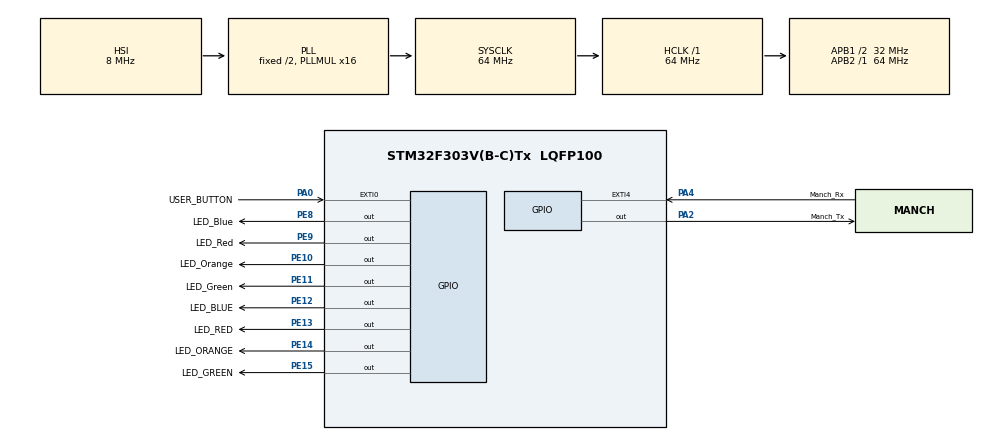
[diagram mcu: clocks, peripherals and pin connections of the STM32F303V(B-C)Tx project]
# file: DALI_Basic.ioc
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Mcu.Family=STM32F3
Mcu.Name=STM32F303V(B-C)Tx
Mcu.Package=LQFP100
NVIC.EXTI0_IRQn=true\:1\:0\:true\:false\:true\:true
NVIC.EXTI4_IRQn=true\:1\:0\:true\:false\:true\:true
NVIC.PriorityGroup=NVIC_PRIORITYGROUP_4
NVIC.TIM2_IRQn=true\:1\:0\:true\:false\:true\:true
PA0.GPIO_Label=USER_BUTTON
PA0.GPIO_PuPd=GPIO_PULLDOWN
PA0.Signal=GPXTI0
PA2.GPIO_Label=Manch_Tx
PA2.GPIO_PuPd=GPIO_PULLDOWN
PA2.Signal=GPIO_Output
PA4.GPIO_Label=Manch_Rx
PA4.GPIO_PuPd=GPIO_PULLDOWN
PA4.Signal=GPXTI4
PE10.GPIO_Label=LED_Orange
PE10.GPIO_PuPd=GPIO_PULLDOWN
PE10.Signal=GPIO_Output
PE11.GPIO_Label=LED_Green
PE11.GPIO_PuPd=GPIO_PULLDOWN
PE11.Signal=GPIO_Output
PE12.GPIO_Label=LED_BLUE
PE12.GPIO_PuPd=GPIO_PULLDOWN
PE12.Signal=GPIO_Output
PE13.GPIO_Label=LED_RED
PE13.GPIO_PuPd=GPIO_PULLDOWN
PE13.Signal=GPIO_Output
PE14.GPIO_Label=LED_ORANGE
PE14.GPIO_PuPd=GPIO_PULLDOWN
PE14.Signal=GPIO_Output
PE15.GPIO_Label=LED_GREEN
PE15.GPIO_PuPd=GPIO_PULLDOWN
PE15.Signal=GPIO_Output
PE8.GPIO_Label=LED_Blue
PE8.GPIO_PuPd=GPIO_PULLDOWN
PE8.Signal=GPIO_Output
PE9.GPIO_Label=LED_Red
PE9.GPIO_PuPd=GPIO_PULLDOWN
PE9.Signal=GPIO_Output
ProjectManager.HeapSize=0x200
ProjectManager.StackSize=0x400
ProjectManager.TargetToolchain=Makefile
RCC.AHBFreq_Value=64000000
RCC.APB1CLKDivider=RCC_HCLK_DIV2
RCC.APB1Freq_Value=32000000
RCC.APB1TimFreq_Value=64000000
RCC.APB2Freq_Value=64000000
RCC.APB2TimFreq_Value=64000000
RCC.CortexFreq_Value=64000000
RCC.HCLKFreq_Value=64000000
RCC.HSE_VALUE=8000000
RCC.HSI_VALUE=8000000
RCC.LSE_VALUE=32768
RCC.PLLMUL=RCC_PLL_MUL16
RCC.SYSCLKFreq_VALUE=64000000
RCC.SYSCLKSourceVirtual=RCC_SYSCLKSOURCE_PLLCLK
RCC.USBFreq_Value=64000000
TIM2.AutoReloadPreload=TIM_AUTORELOAD_PRELOAD_ENABLE
TIM2.Period=103
TIM2.Prescaler=63
VP_TIM2_VS_ClockSourceINT.Mode=Internal
board=DALI_Basic

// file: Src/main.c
/**
  ******************************************************************************
  * File Name          : main.c
  * Description        : Main program body
  ******************************************************************************
  ** This notice applies to any and all portions of this file
  * that are not between comment pairs USER CODE BEGIN and
  * USER CODE END. Other portions of this file, whether
  * inserted by the user or by software development tools
  * are owned by their respective copyright owners.
  *
  * COPYRIGHT(c) 2017 STMicroelectronics
  *
  * Redistribution and use in source and binary forms, with or without modification,
  * are permitted provided that the following conditions are met:
  *   1. Redistributions of source code must retain the above copyright notice,
  *      this list of conditions and the following disclaimer.
  *   2. Redistributions in binary form must reproduce the above copyright notice,
  *      this list of conditions and the following disclaimer in the documentation
  *      and/or other materials provided with the distribution.
  *   3. Neither the name of STMicroelectronics nor the names of its contributors
  *      may be used to endorse or promote products derived from this software
  *      without specific prior written permission.
  *
  * THIS SOFTWARE IS PROVIDED BY THE COPYRIGHT HOLDERS AND CONTRIBUTORS "AS IS"
  * AND ANY EXPRESS OR IMPLIED WARRANTIES, INCLUDING, BUT NOT LIMITED TO, THE
  * IMPLIED WARRANTIES OF MERCHANTABILITY AND FITNESS FOR A PARTICULAR PURPOSE ARE
  * DISCLAIMED. IN NO EVENT SHALL THE COPYRIGHT HOLDER OR CONTRIBUTORS BE LIABLE
  * FOR ANY DIRECT, INDIRECT, INCIDENTAL, SPECIAL, EXEMPLARY, OR CONSEQUENTIAL
  * DAMAGES (INCLUDING, BUT NOT LIMITED TO, PROCUREMENT OF SUBSTITUTE GOODS OR
  * SERVICES; LOSS OF USE, DATA, OR PROFITS; OR BUSINESS INTERRUPTION) HOWEVER
  * CAUSED AND ON ANY THEORY OF LIABILITY, WHETHER IN CONTRACT, STRICT LIABILITY,
  * OR TORT (INCLUDING NEGLIGENCE OR OTHERWISE) ARISING IN ANY WAY OUT OF THE USE
  * OF THIS SOFTWARE, EVEN IF ADVISED OF THE POSSIBILITY OF SUCH DAMAGE.
  *
  ******************************************************************************
  */

#include "main.h"
#include "stm32f3xx_hal.h"

/* USER CODE BEGIN Includes */
/* ++++++++++ Includes ++++++++++++++++++++++++++++++++++++++++++++++++++++++*/
// skipped timer_slave.h as I don't need it!
#include "DALI_Slave_ll.h"
#include "DALI_Slave_defs.h"
#include "DALI_defs.h"
/* USER CODE END Includes */

TIM_HandleTypeDef htim2;

/* USER CODE BEGIN PV */
/* Private variables ---------------------------------------------------------*/

/* USER CODE END PV */

void SystemClock_Config(void);
static void MX_GPIO_Init(void);
static void MX_TIM2_Init(void);

/* USER CODE BEGIN PFP */
/* Private function prototypes -----------------------------------------------*/

/* USER CODE END PFP */

int main(void)
{

  /* MCU Configuration----------------------------------------------------------*/

  /* Reset of all peripherals, Initializes the Flash interface and the Systick. */
  HAL_Init();

  /* Configure the system clock */
  SystemClock_Config();

  /* Initialize all configured peripherals */
  MX_GPIO_Init();
  MX_TIM2_Init();

  /* Infinite loop */
  while (1)
  {

  }

}

/** System Clock Configuration
*/
void SystemClock_Config(void)
{

  RCC_OscInitTypeDef RCC_OscInitStruct;
  RCC_ClkInitTypeDef RCC_ClkInitStruct;

    /**Initializes the CPU, AHB and APB busses clocks
    */
  RCC_OscInitStruct.OscillatorType = RCC_OSCILLATORTYPE_HSI;
  RCC_OscInitStruct.HSIState = RCC_HSI_ON;
  RCC_OscInitStruct.HSICalibrationValue = 16;
  RCC_OscInitStruct.PLL.PLLState = RCC_PLL_ON;
  RCC_OscInitStruct.PLL.PLLSource = RCC_PLLSOURCE_HSI;
  RCC_OscInitStruct.PLL.PLLMUL = RCC_PLL_MUL16;
  if (HAL_RCC_OscConfig(&RCC_OscInitStruct) != HAL_OK)
  {
    _Error_Handler(__FILE__, __LINE__);
  }

    /**Initializes the CPU, AHB and APB busses clocks
    */
  RCC_ClkInitStruct.ClockType = RCC_CLOCKTYPE_HCLK|RCC_CLOCKTYPE_SYSCLK
                              |RCC_CLOCKTYPE_PCLK1|RCC_CLOCKTYPE_PCLK2;
  RCC_ClkInitStruct.SYSCLKSource = RCC_SYSCLKSOURCE_PLLCLK;
  RCC_ClkInitStruct.AHBCLKDivider = RCC_SYSCLK_DIV1;
  RCC_ClkInitStruct.APB1CLKDivider = RCC_HCLK_DIV2;
  RCC_ClkInitStruct.APB2CLKDivider = RCC_HCLK_DIV1;

  if (HAL_RCC_ClockConfig(&RCC_ClkInitStruct, FLASH_LATENCY_2) != HAL_OK)
  {
    _Error_Handler(__FILE__, __LINE__);
  }

    /**Configure the Systick interrupt time
    */
  HAL_SYSTICK_Config(HAL_RCC_GetHCLKFreq()/1000);

    /**Configure the Systick
    */
  HAL_SYSTICK_CLKSourceConfig(SYSTICK_CLKSOURCE_HCLK);

  /* SysTick_IRQn interrupt configuration */
  HAL_NVIC_SetPriority(SysTick_IRQn, 0, 0);
}

/* TIM2 init function */
static void MX_TIM2_Init(void)
{

  TIM_ClockConfigTypeDef sClockSourceConfig;
  TIM_MasterConfigTypeDef sMasterConfig;

  htim2.Instance = TIM2;
  htim2.Init.Prescaler = 63;
  htim2.Init.CounterMode = TIM_COUNTERMODE_UP;
  htim2.Init.Period = 103;
  htim2.Init.ClockDivision = TIM_CLOCKDIVISION_DIV1;
  htim2.Init.AutoReloadPreload = TIM_AUTORELOAD_PRELOAD_ENABLE;
  if (HAL_TIM_Base_Init(&htim2) != HAL_OK)
  {
    _Error_Handler(__FILE__, __LINE__);
  }

  sClockSourceConfig.ClockSource = TIM_CLOCKSOURCE_INTERNAL;
  if (HAL_TIM_ConfigClockSource(&htim2, &sClockSourceConfig) != HAL_OK)
  {
    _Error_Handler(__FILE__, __LINE__);
  }

  sMasterConfig.MasterOutputTrigger = TIM_TRGO_RESET;
  sMasterConfig.MasterSlaveMode = TIM_MASTERSLAVEMODE_DISABLE;
  if (HAL_TIMEx_MasterConfigSynchronization(&htim2, &sMasterConfig) != HAL_OK)
  {
    _Error_Handler(__FILE__, __LINE__);
  }

}

/** Configure pins as
        * Analog
        * Input
        * Output
        * EVENT_OUT
        * EXTI
*/
static void MX_GPIO_Init(void)
{

  GPIO_InitTypeDef GPIO_InitStruct;

  /* GPIO Ports Clock Enable */
  __HAL_RCC_GPIOA_CLK_ENABLE();
  __HAL_RCC_GPIOE_CLK_ENABLE();

  /*Configure GPIO pin Output Level */
  HAL_GPIO_WritePin(Manch_Tx_GPIO_Port, Manch_Tx_Pin, GPIO_PIN_RESET);

  /*Configure GPIO pin Output Level */
  HAL_GPIO_WritePin(GPIOE, LED_Blue_Pin|LED_Red_Pin|LED_Orange_Pin|LED_Green_Pin
                          |LED_BLUE_Pin|LED_RED_Pin|LED_ORANGE_Pin|LED_GREEN_Pin, GPIO_PIN_RESET);

  /*Configure GPIO pins : USER_BUTTON_Pin Manch_Rx_Pin */
  GPIO_InitStruct.Pin = USER_BUTTON_Pin|Manch_Rx_Pin;
  GPIO_InitStruct.Mode = GPIO_MODE_IT_RISING;
  GPIO_InitStruct.Pull = GPIO_PULLDOWN;
  HAL_GPIO_Init(GPIOA, &GPIO_InitStruct);

  /*Configure GPIO pin : Manch_Tx_Pin */
  GPIO_InitStruct.Pin = Manch_Tx_Pin;
  GPIO_InitStruct.Mode = GPIO_MODE_OUTPUT_PP;
  GPIO_InitStruct.Pull = GPIO_PULLDOWN;
  GPIO_InitStruct.Speed = GPIO_SPEED_FREQ_LOW;
  HAL_GPIO_Init(Manch_Tx_GPIO_Port, &GPIO_InitStruct);

  /*Configure GPIO pins : LED_Blue_Pin LED_Red_Pin LED_Orange_Pin LED_Green_Pin
                           LED_BLUE_Pin LED_RED_Pin LED_ORANGE_Pin LED_GREEN_Pin */
  GPIO_InitStruct.Pin = LED_Blue_Pin|LED_Red_Pin|LED_Orange_Pin|LED_Green_Pin
                          |LED_BLUE_Pin|LED_RED_Pin|LED_ORANGE_Pin|LED_GREEN_Pin;
  GPIO_InitStruct.Mode = GPIO_MODE_OUTPUT_PP;
  GPIO_InitStruct.Pull = GPIO_PULLDOWN;
  GPIO_InitStruct.Speed = GPIO_SPEED_FREQ_LOW;
  HAL_GPIO_Init(GPIOE, &GPIO_InitStruct);

  /* EXTI interrupt init*/
  HAL_NVIC_SetPriority(EXTI0_IRQn, 1, 0);
  HAL_NVIC_EnableIRQ(EXTI0_IRQn);

  HAL_NVIC_SetPriority(EXTI4_IRQn, 1, 0);
  HAL_NVIC_EnableIRQ(EXTI4_IRQn);

}

void _Error_Handler(char * file, int line)
{
  while(1)
  {
  }
}

/************************ (C) COPYRIGHT STMicroelectronics *****END OF FILE****/
